VERSION "f33"

NS_ :

BS_:

BU_: C70 VC BMS CHG DASH PBX

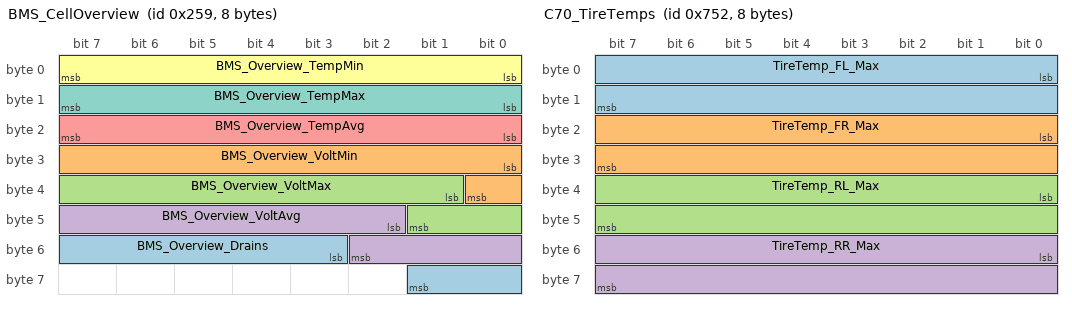
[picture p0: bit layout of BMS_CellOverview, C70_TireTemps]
BO_ 601 BMS_CellOverview: 8 BMS
 SG_ BMS_Overview_Drains : 51|7@1+ (1,0) [0|76] "" Vector__XXX
 SG_ BMS_Overview_VoltMin : 24|9@1+ (0.01,0) [0|5.12] "V"  DASH
 SG_ BMS_Overview_VoltMax : 33|9@1+ (0.01,0) [0|5.12] "V"  DASH
 SG_ BMS_Overview_VoltAvg : 42|9@1+ (0.01,0) [0|5.12] "V" Vector__XXX
 SG_ BMS_Overview_TempAvg : 16|8@1- (1,0) [-128|127] "C" Vector__XXX
 SG_ BMS_Overview_TempMin : 0|8@1- (1,0) [-128|127] "C" Vector__XXX
 SG_ BMS_Overview_TempMax : 8|8@1- (1,0) [-128|127] "C" Vector__XXX

BO_ 1791 C70_BrakePressures: 8 C70
 SG_ C70_BrakePressureFront : 0|16@1- (0.5,2500) [0|5000] "psi" Vector__XXX
 SG_ C70_BrakePressureRear : 16|16@1- (0.2,1250) [0|2500] "psi" Vector__XXX

BO_ 1874 C70_TireTemps: 8 C70
 SG_ TireTemp_FL_Max : 0|16@1+ (0.01,-100) [-20|950] "degC" Vector__XXX
 SG_ TireTemp_FR_Max : 16|16@1+ (0.01,-100) [-20|950] "degC" Vector__XXX
 SG_ TireTemp_RL_Max : 32|16@1+ (0.01,-100) [-20|950] "degC" Vector__XXX
 SG_ TireTemp_RR_Max : 48|16@1+ (0.01,-100) [-20|950] "degC" Vector__XXX

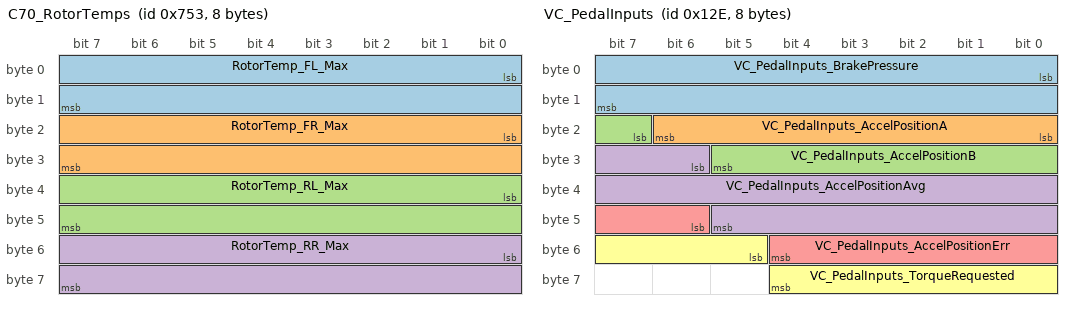
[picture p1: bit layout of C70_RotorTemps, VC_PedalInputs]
BO_ 1875 C70_RotorTemps: 8 C70
 SG_ RotorTemp_FL_Max : 0|16@1+ (0.01,-100) [-20|950] "degC" Vector__XXX
 SG_ RotorTemp_FR_Max : 16|16@1+ (0.01,-100) [-20|950] "degC" Vector__XXX
 SG_ RotorTemp_RL_Max : 32|16@1+ (0.01,-100) [-20|950] "degC" Vector__XXX
 SG_ RotorTemp_RR_Max : 48|16@1+ (0.01,-100) [-20|950] "degC" Vector__XXX

BO_ 301 VC_Status: 8 VC
 SG_ VC_Status_VehicleState : 0|4@1+ (1,0) [0|15] ""  DASH

BO_ 302 VC_PedalInputs: 8 VC
 SG_ VC_PedalInputs_BrakePressure : 0|16@1+ (0.1,0) [0|3000] "psi" Vector__XXX
 SG_ VC_PedalInputs_AccelPositionA : 16|7@1+ (1,0) [0|100] "%" Vector__XXX
 SG_ VC_PedalInputs_AccelPositionB : 23|7@1+ (1,0) [0|100] "%" Vector__XXX
 SG_ VC_PedalInputs_AccelPositionAvg : 30|16@1+ (0.1,0) [0|100] "%" Vector__XXX
 SG_ VC_PedalInputs_AccelPositionErr : 46|7@1+ (1,0) [0|100] "%" Vector__XXX
 SG_ VC_PedalInputs_TorqueRequested : 53|8@1+ (1,0) [0|254] "Nm" Vector__XXX

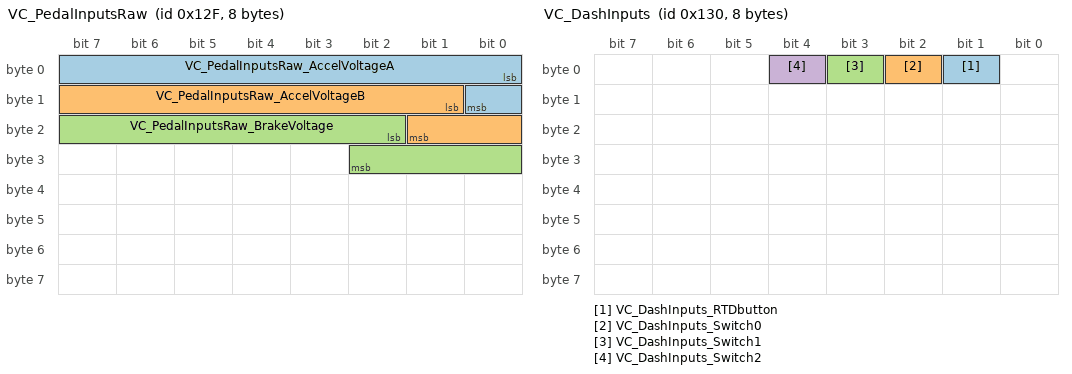
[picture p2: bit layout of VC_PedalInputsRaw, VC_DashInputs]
BO_ 303 VC_PedalInputsRaw: 8 VC
 SG_ VC_PedalInputsRaw_AccelVoltageA : 0|9@1+ (0.01,0) [0|5] "V" Vector__XXX
 SG_ VC_PedalInputsRaw_AccelVoltageB : 9|9@1+ (0.01,0) [0|5] "V" Vector__XXX
 SG_ VC_PedalInputsRaw_BrakeVoltage : 18|9@1+ (0.01,0) [0|5] "V" Vector__XXX

BO_ 304 VC_DashInputs: 8 VC
 SG_ VC_DashInputs_RTDbutton : 1|1@1+ (1,0) [0|1] "" Vector__XXX
 SG_ VC_DashInputs_Switch0 : 2|1@1+ (1,0) [0|1] "" Vector__XXX
 SG_ VC_DashInputs_Switch1 : 3|1@1+ (1,0) [0|1] "" Vector__XXX
 SG_ VC_DashInputs_Switch2 : 4|1@1+ (1,0) [0|1] "" Vector__XXX

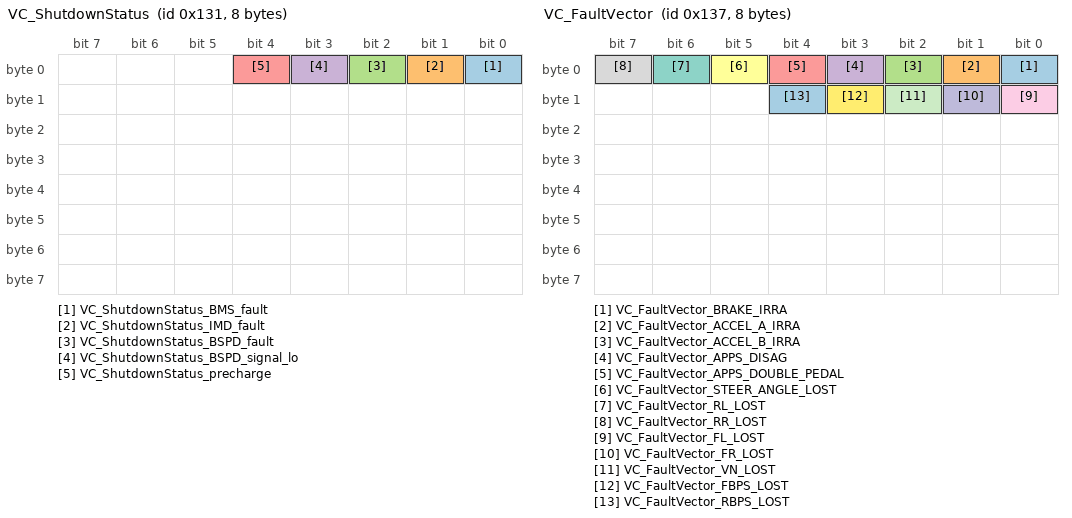
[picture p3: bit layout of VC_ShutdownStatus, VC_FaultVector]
BO_ 305 VC_ShutdownStatus: 8 VC
 SG_ VC_ShutdownStatus_BMS_fault : 0|1@1+ (1,0) [0|1] "" Vector__XXX
 SG_ VC_ShutdownStatus_IMD_fault : 1|1@1+ (1,0) [0|1] "" Vector__XXX
 SG_ VC_ShutdownStatus_BSPD_fault : 2|1@1+ (1,0) [0|1] "" Vector__XXX
 SG_ VC_ShutdownStatus_BSPD_signal_lo : 3|1@1+ (1,0) [0|1] "" Vector__XXX
 SG_ VC_ShutdownStatus_precharge : 4|1@1+ (1,0) [0|1] "" Vector__XXX

BO_ 311 VC_FaultVector: 8 VC
 SG_ VC_FaultVector_BRAKE_IRRA : 0|1@1+ (1,0) [0|1] ""  DASH
 SG_ VC_FaultVector_ACCEL_A_IRRA : 1|1@1+ (1,0) [0|1] ""  DASH
 SG_ VC_FaultVector_ACCEL_B_IRRA : 2|1@1+ (1,0) [0|1] ""  DASH
 SG_ VC_FaultVector_APPS_DISAG : 3|1@1+ (1,0) [0|1] ""  DASH
 SG_ VC_FaultVector_APPS_DOUBLE_PEDAL : 4|1@1+ (1,0) [0|1] ""  DASH
 SG_ VC_FaultVector_STEER_ANGLE_LOST : 5|1@1+ (1,0) [0|1] ""  DASH
 SG_ VC_FaultVector_RL_LOST : 6|1@1+ (1,0) [0|1] ""  DASH
 SG_ VC_FaultVector_RR_LOST : 7|1@1+ (1,0) [0|1] ""  DASH
 SG_ VC_FaultVector_FL_LOST : 8|1@1+ (1,0) [0|1] ""  DASH
 SG_ VC_FaultVector_FR_LOST : 9|1@1+ (1,0) [0|1] ""  DASH
 SG_ VC_FaultVector_VN_LOST : 10|1@1+ (1,0) [0|1] ""  DASH
 SG_ VC_FaultVector_FBPS_LOST : 11|1@1+ (1,0) [0|1] ""  DASH
 SG_ VC_FaultVector_RBPS_LOST : 12|1@1+ (1,0) [0|1] ""  DASH

BO_ 315 VC_HardFaultIndicator: 8 VC
 SG_ VC_HardFaultIndicator_task : 0|4@1+ (1,0) [0|15] ""  DASH

BO_ 316 VC_RTDSRequest: 8 VC
 SG_ VC_RequestRTDS : 0|1@1+ (1,0) [0|1] "" Vector__XXX

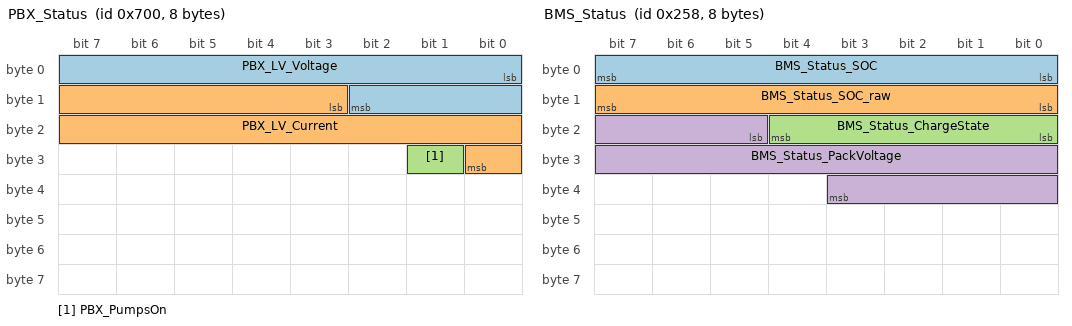
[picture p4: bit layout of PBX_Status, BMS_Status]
BO_ 1792 PBX_Status: 8 PBX
 SG_ PBX_LV_Voltage : 0|11@1+ (0.01,0) [0|20] "V" Vector__XXX
 SG_ PBX_LV_Current : 11|14@1+ (0.01,0) [0|100] "A" Vector__XXX
 SG_ PBX_PumpsOn : 25|1@1+ (1,0) [0|1] ""  VC

BO_ 514 BMS_Current_Limit: 8 BMS
 SG_ D1_Max_Discharge_Current : 0|16@1+ (1,0) [0|1000] "A" Vector__XXX
 SG_ D2_Max_Charge_Current : 16|16@1+ (1,0) [0|1000] "A" Vector__XXX

BO_ 600 BMS_Status: 8 BMS
 SG_ BMS_Status_SOC : 0|8@1+ (1,0) [0|100] "%"  DASH
 SG_ BMS_Status_SOC_raw : 8|8@1+ (1,0) [0|100] "%" Vector__XXX
 SG_ BMS_Status_ChargeState : 16|5@1+ (1,0) [0|5] "" Vector__XXX
 SG_ BMS_Status_PackVoltage : 21|15@1+ (0.1,0) [0|400] "V"  DASH

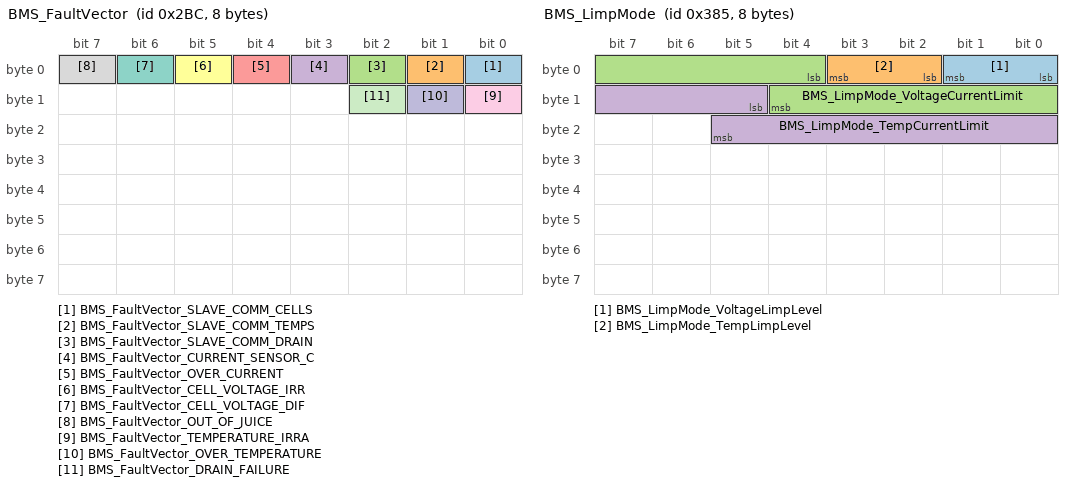
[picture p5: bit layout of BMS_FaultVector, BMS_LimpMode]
BO_ 700 BMS_FaultVector: 8 BMS
 SG_ BMS_FaultVector_SLAVE_COMM_CELLS : 0|1@1+ (1,0) [0|1] ""  DASH
 SG_ BMS_FaultVector_SLAVE_COMM_TEMPS : 1|1@1+ (1,0) [0|1] ""  DASH
 SG_ BMS_FaultVector_SLAVE_COMM_DRAIN : 2|1@1+ (1,0) [0|1] ""  DASH
 SG_ BMS_FaultVector_CURRENT_SENSOR_C : 3|1@1+ (1,0) [0|1] ""  DASH
 SG_ BMS_FaultVector_OVER_CURRENT : 4|1@1+ (1,0) [0|1] ""  DASH
 SG_ BMS_FaultVector_CELL_VOLTAGE_IRR : 5|1@1+ (1,0) [0|1] ""  DASH
 SG_ BMS_FaultVector_CELL_VOLTAGE_DIF : 6|1@1+ (1,0) [0|1] ""  DASH
 SG_ BMS_FaultVector_OUT_OF_JUICE : 7|1@1+ (1,0) [0|1] ""  DASH
 SG_ BMS_FaultVector_TEMPERATURE_IRRA : 8|1@1+ (1,0) [0|1] ""  DASH
 SG_ BMS_FaultVector_OVER_TEMPERATURE : 9|1@1+ (1,0) [0|1] ""  DASH
 SG_ BMS_FaultVector_DRAIN_FAILURE : 10|1@1+ (1,0) [0|1] ""  DASH

BO_ 701 BMS_FaultAlert: 8 BMS
 SG_ BMS_FaultAlert_code M : 0|6@1+ (1,0) [0|63] "" Vector__XXX
 SG_ BMS_FaultAlert_cell_comm_slave_b m0 : 6|8@1+ (1,0) [0|255] "" Vector__XXX
 SG_ BMS_FaultAlert_temp_comm_slave_b m1 : 6|8@1+ (1,0) [0|255] "" Vector__XXX
 SG_ BMS_FaultAlert_drain_comm_slave_ m2 : 6|8@1+ (1,0) [0|255] "" Vector__XXX
 SG_ BMS_FaultAlert_adc_error_code m3 : 6|8@1+ (1,0) [0|255] "" Vector__XXX
 SG_ BMS_FaultAlert_current m4 : 6|32@1+ (0.001,0) [0|2000] "A" Vector__XXX
 SG_ BMS_FaultAlert_irrational_voltag m5 : 6|9@1+ (0.01,0) [0|5.12] "V" Vector__XXX
 SG_ BMS_FaultAlert_voltage_diff m6 : 6|9@1+ (0.01,0) [0|5.12] "V" Vector__XXX
 SG_ BMS_FaultAlert_lowest_cell_volta m7 : 6|9@1+ (0.01,0) [0|5.12] "V" Vector__XXX
 SG_ BMS_FaultAlert_irrational_temper m8 : 6|16@1+ (0.01,0) [-327.68|327.67] "V" Vector__XXX
 SG_ BMS_FaultAlert_over_temperature m9 : 6|16@1+ (0.01,0) [-327.68|327.67] "V" Vector__XXX
 SG_ BMS_FaultAlert_failed_drain_cell m10 : 6|8@1+ (1,0) [0|255] "" Vector__XXX

BO_ 702 BMS_Voltages: 8 BMS
 SG_ BMS_Voltages_mux M : 0|8@1+ (1,0) [0|12] "" Vector__XXX
 SG_ BMS_Voltages_A1 m0 : 8|9@1+ (0.01,0) [0|5.12] "V" Vector__XXX
 SG_ BMS_Voltages_A2 m0 : 17|9@1+ (0.01,0) [0|5.12] "V" Vector__XXX
 SG_ BMS_Voltages_A3 m0 : 26|9@1+ (0.01,0) [0|5.12] "V" Vector__XXX
 SG_ BMS_Voltages_A4 m0 : 35|9@1+ (0.01,0) [0|5.12] "V" Vector__XXX
 SG_ BMS_Voltages_A5 m0 : 44|9@1+ (0.01,0) [0|5.12] "V" Vector__XXX
 SG_ BMS_Voltages_A6 m0 : 53|9@1+ (0.01,0) [0|5.12] "V" Vector__XXX
 SG_ BMS_Voltages_A7 m1 : 8|9@1+ (0.01,0) [0|5.12] "V" Vector__XXX
 SG_ BMS_Voltages_A8 m1 : 17|9@1+ (0.01,0) [0|5.12] "V" Vector__XXX
 SG_ BMS_Voltages_A9 m1 : 26|9@1+ (0.01,0) [0|5.12] "V" Vector__XXX
 SG_ BMS_Voltages_A10 m1 : 35|9@1+ (0.01,0) [0|5.12] "V" Vector__XXX
 SG_ BMS_Voltages_A11 m1 : 44|9@1+ (0.01,0) [0|5.12] "V" Vector__XXX
 SG_ BMS_Voltages_A12 m1 : 53|9@1+ (0.01,0) [0|5.12] "V" Vector__XXX
 SG_ BMS_Voltages_A13 m2 : 8|9@1+ (0.01,0) [0|5.12] "V" Vector__XXX
 SG_ BMS_Voltages_A14 m2 : 17|9@1+ (0.01,0) [0|5.12] "V" Vector__XXX
 SG_ BMS_Voltages_A15 m2 : 26|9@1+ (0.01,0) [0|5.12] "V" Vector__XXX
 SG_ BMS_Voltages_A16 m2 : 35|9@1+ (0.01,0) [0|5.12] "V" Vector__XXX
 SG_ BMS_Voltages_A17 m2 : 44|9@1+ (0.01,0) [0|5.12] "V" Vector__XXX
 SG_ BMS_Voltages_A18 m2 : 53|9@1+ (0.01,0) [0|5.12] "V" Vector__XXX
 SG_ BMS_Voltages_A19 m3 : 8|9@1+ (0.01,0) [0|5.12] "V" Vector__XXX
 SG_ BMS_Voltages_B1 m3 : 17|9@1+ (0.01,0) [0|5.12] "V" Vector__XXX
 SG_ BMS_Voltages_B2 m3 : 26|9@1+ (0.01,0) [0|5.12] "V" Vector__XXX
 SG_ BMS_Voltages_B3 m3 : 35|9@1+ (0.01,0) [0|5.12] "V" Vector__XXX
 SG_ BMS_Voltages_B4 m3 : 44|9@1+ (0.01,0) [0|5.12] "V" Vector__XXX
 SG_ BMS_Voltages_B5 m3 : 53|9@1+ (0.01,0) [0|5.12] "V" Vector__XXX
 SG_ BMS_Voltages_B6 m4 : 8|9@1+ (0.01,0) [0|5.12] "V" Vector__XXX
 SG_ BMS_Voltages_B7 m4 : 17|9@1+ (0.01,0) [0|5.12] "V" Vector__XXX
 SG_ BMS_Voltages_B8 m4 : 26|9@1+ (0.01,0) [0|5.12] "V" Vector__XXX
 SG_ BMS_Voltages_B9 m4 : 35|9@1+ (0.01,0) [0|5.12] "V" Vector__XXX
 SG_ BMS_Voltages_B10 m4 : 44|9@1+ (0.01,0) [0|5.12] "V" Vector__XXX
 SG_ BMS_Voltages_B11 m4 : 53|9@1+ (0.01,0) [0|5.12] "V" Vector__XXX
 SG_ BMS_Voltages_B12 m5 : 8|9@1+ (0.01,0) [0|5.12] "V" Vector__XXX
 SG_ BMS_Voltages_B13 m5 : 17|9@1+ (0.01,0) [0|5.12] "V" Vector__XXX
 SG_ BMS_Voltages_B14 m5 : 26|9@1+ (0.01,0) [0|5.12] "V" Vector__XXX
 SG_ BMS_Voltages_B15 m5 : 35|9@1+ (0.01,0) [0|5.12] "V" Vector__XXX
 SG_ BMS_Voltages_B16 m5 : 44|9@1+ (0.01,0) [0|5.12] "V" Vector__XXX
 SG_ BMS_Voltages_B17 m5 : 53|9@1+ (0.01,0) [0|5.12] "V" Vector__XXX
 SG_ BMS_Voltages_B18 m6 : 8|9@1+ (0.01,0) [0|5.12] "V" Vector__XXX
 SG_ BMS_Voltages_B19 m6 : 17|9@1+ (0.01,0) [0|5.12] "V" Vector__XXX
 SG_ BMS_Voltages_C1 m6 : 26|9@1+ (0.01,0) [0|5.12] "V" Vector__XXX
 SG_ BMS_Voltages_C2 m6 : 35|9@1+ (0.01,0) [0|5.12] "V" Vector__XXX
 SG_ BMS_Voltages_C3 m6 : 44|9@1+ (0.01,0) [0|5.12] "V" Vector__XXX
 SG_ BMS_Voltages_C4 m6 : 53|9@1+ (0.01,0) [0|5.12] "V" Vector__XXX
 SG_ BMS_Voltages_C5 m7 : 8|9@1+ (0.01,0) [0|5.12] "V" Vector__XXX
 SG_ BMS_Voltages_C6 m7 : 17|9@1+ (0.01,0) [0|5.12] "V" Vector__XXX
 SG_ BMS_Voltages_C7 m7 : 26|9@1+ (0.01,0) [0|5.12] "V" Vector__XXX
 SG_ BMS_Voltages_C8 m7 : 35|9@1+ (0.01,0) [0|5.12] "V" Vector__XXX
 SG_ BMS_Voltages_C9 m7 : 44|9@1+ (0.01,0) [0|5.12] "V" Vector__XXX
 SG_ BMS_Voltages_C10 m7 : 53|9@1+ (0.01,0) [0|5.12] "V" Vector__XXX
 SG_ BMS_Voltages_C11 m8 : 8|9@1+ (0.01,0) [0|5.12] "V" Vector__XXX
 SG_ BMS_Voltages_C12 m8 : 17|9@1+ (0.01,0) [0|5.12] "V" Vector__XXX
 SG_ BMS_Voltages_C13 m8 : 26|9@1+ (0.01,0) [0|5.12] "V" Vector__XXX
 SG_ BMS_Voltages_C14 m8 : 35|9@1+ (0.01,0) [0|5.12] "V" Vector__XXX
 SG_ BMS_Voltages_C15 m8 : 44|9@1+ (0.01,0) [0|5.12] "V" Vector__XXX
 SG_ BMS_Voltages_C16 m8 : 53|9@1+ (0.01,0) [0|5.12] "V" Vector__XXX
 SG_ BMS_Voltages_C17 m9 : 8|9@1+ (0.01,0) [0|5.12] "V" Vector__XXX
 SG_ BMS_Voltages_C18 m9 : 17|9@1+ (0.01,0) [0|5.12] "V" Vector__XXX
 SG_ BMS_Voltages_C19 m9 : 26|9@1+ (0.01,0) [0|5.12] "V" Vector__XXX
 SG_ BMS_Voltages_D1 m9 : 35|9@1+ (0.01,0) [0|5.12] "V" Vector__XXX
 SG_ BMS_Voltages_D2 m9 : 44|9@1+ (0.01,0) [0|5.12] "V" Vector__XXX
 SG_ BMS_Voltages_D3 m9 : 53|9@1+ (0.01,0) [0|5.12] "V" Vector__XXX
 SG_ BMS_Voltages_D4 m10 : 8|9@1+ (0.01,0) [0|5.12] "V" Vector__XXX
 SG_ BMS_Voltages_D5 m10 : 17|9@1+ (0.01,0) [0|5.12] "V" Vector__XXX
 SG_ BMS_Voltages_D6 m10 : 26|9@1+ (0.01,0) [0|5.12] "V" Vector__XXX
 SG_ BMS_Voltages_D7 m10 : 35|9@1+ (0.01,0) [0|5.12] "V" Vector__XXX
 SG_ BMS_Voltages_D8 m10 : 44|9@1+ (0.01,0) [0|5.12] "V" Vector__XXX
 SG_ BMS_Voltages_D9 m10 : 53|9@1+ (0.01,0) [0|5.12] "V" Vector__XXX
 SG_ BMS_Voltages_D10 m11 : 8|9@1+ (0.01,0) [0|5.12] "V" Vector__XXX
 SG_ BMS_Voltages_D11 m11 : 17|9@1+ (0.01,0) [0|5.12] "V" Vector__XXX
 SG_ BMS_Voltages_D12 m11 : 26|9@1+ (0.01,0) [0|5.12] "V" Vector__XXX
 SG_ BMS_Voltages_D13 m11 : 35|9@1+ (0.01,0) [0|5.12] "V" Vector__XXX
 SG_ BMS_Voltages_D14 m11 : 44|9@1+ (0.01,0) [0|5.12] "V" Vector__XXX
 SG_ BMS_Voltages_D15 m11 : 53|9@1+ (0.01,0) [0|5.12] "V" Vector__XXX
 SG_ BMS_Voltages_D16 m12 : 8|9@1+ (0.01,0) [0|5.12] "V" Vector__XXX
 SG_ BMS_Voltages_D17 m12 : 17|9@1+ (0.01,0) [0|5.12] "V" Vector__XXX
 SG_ BMS_Voltages_D18 m12 : 26|9@1+ (0.01,0) [0|5.12] "V" Vector__XXX
 SG_ BMS_Voltages_D19 m12 : 35|9@1+ (0.01,0) [0|5.12] "V" Vector__XXX

BO_ 703 BMS_ThermistorVoltages: 8 BMS
 SG_ BMS_ThermistorVoltages_mux M : 0|3@1+ (1,0) [0|5] "" Vector__XXX
 SG_ BMS_ThermistorVoltages_A1 m0 : 3|9@1+ (0.01,0) [0|5.12] "V" Vector__XXX
 SG_ BMS_ThermistorVoltages_A2 m0 : 12|9@1+ (0.01,0) [0|5.12] "V" Vector__XXX
 SG_ BMS_ThermistorVoltages_A3 m0 : 21|9@1+ (0.01,0) [0|5.12] "V" Vector__XXX
 SG_ BMS_ThermistorVoltages_A4 m0 : 30|9@1+ (0.01,0) [0|5.12] "V" Vector__XXX
 SG_ BMS_ThermistorVoltages_A5 m0 : 39|9@1+ (0.01,0) [0|5.12] "V" Vector__XXX
 SG_ BMS_ThermistorVoltages_A6 m0 : 48|9@1+ (0.01,0) [0|5.12] "V" Vector__XXX
 SG_ BMS_ThermistorVoltages_A7 m1 : 3|9@1+ (0.01,0) [0|5.12] "V" Vector__XXX
 SG_ BMS_ThermistorVoltages_A8 m1 : 12|9@1+ (0.01,0) [0|5.12] "V" Vector__XXX
 SG_ BMS_ThermistorVoltages_B1 m1 : 21|9@1+ (0.01,0) [0|5.12] "V" Vector__XXX
 SG_ BMS_ThermistorVoltages_B2 m1 : 30|9@1+ (0.01,0) [0|5.12] "V" Vector__XXX
 SG_ BMS_ThermistorVoltages_B3 m1 : 39|9@1+ (0.01,0) [0|5.12] "V" Vector__XXX
 SG_ BMS_ThermistorVoltages_B4 m1 : 48|9@1+ (0.01,0) [0|5.12] "V" Vector__XXX
 SG_ BMS_ThermistorVoltages_B5 m2 : 3|9@1+ (0.01,0) [0|5.12] "V" Vector__XXX
 SG_ BMS_ThermistorVoltages_B6 m2 : 12|9@1+ (0.01,0) [0|5.12] "V" Vector__XXX
 SG_ BMS_ThermistorVoltages_B7 m2 : 21|9@1+ (0.01,0) [0|5.12] "V" Vector__XXX
 SG_ BMS_ThermistorVoltages_B8 m2 : 30|9@1+ (0.01,0) [0|5.12] "V" Vector__XXX
 SG_ BMS_ThermistorVoltages_C1 m2 : 39|9@1+ (0.01,0) [0|5.12] "V" Vector__XXX
 SG_ BMS_ThermistorVoltages_C2 m2 : 48|9@1+ (0.01,0) [0|5.12] "V" Vector__XXX
 SG_ BMS_ThermistorVoltages_C3 m3 : 3|9@1+ (0.01,0) [0|5.12] "V" Vector__XXX
 SG_ BMS_ThermistorVoltages_C4 m3 : 12|9@1+ (0.01,0) [0|5.12] "V" Vector__XXX
 SG_ BMS_ThermistorVoltages_C5 m3 : 21|9@1+ (0.01,0) [0|5.12] "V" Vector__XXX
 SG_ BMS_ThermistorVoltages_C6 m3 : 30|9@1+ (0.01,0) [0|5.12] "V" Vector__XXX
 SG_ BMS_ThermistorVoltages_C7 m3 : 39|9@1+ (0.01,0) [0|5.12] "V" Vector__XXX
 SG_ BMS_ThermistorVoltages_C8 m3 : 48|9@1+ (0.01,0) [0|5.12] "V" Vector__XXX
 SG_ BMS_ThermistorVoltages_D1 m4 : 3|9@1+ (0.01,0) [0|5.12] "V" Vector__XXX
 SG_ BMS_ThermistorVoltages_D2 m4 : 12|9@1+ (0.01,0) [0|5.12] "V" Vector__XXX
 SG_ BMS_ThermistorVoltages_D3 m4 : 21|9@1+ (0.01,0) [0|5.12] "V" Vector__XXX
 SG_ BMS_ThermistorVoltages_D4 m4 : 30|9@1+ (0.01,0) [0|5.12] "V" Vector__XXX
 SG_ BMS_ThermistorVoltages_D5 m4 : 39|9@1+ (0.01,0) [0|5.12] "V" Vector__XXX
 SG_ BMS_ThermistorVoltages_D6 m4 : 48|9@1+ (0.01,0) [0|5.12] "V" Vector__XXX
 SG_ BMS_ThermistorVoltages_D7 m5 : 3|9@1+ (0.01,0) [0|5.12] "V" Vector__XXX
 SG_ BMS_ThermistorVoltages_D8 m5 : 12|9@1+ (0.01,0) [0|5.12] "V" Vector__XXX

BO_ 704 BMS_Temperatures: 8 BMS
 SG_ BMS_Temperatures_mux M : 0|3@1+ (1,0) [0|4] "" Vector__XXX
 SG_ BMS_Temperatures_A1 m0 : 3|8@1- (1,0) [-128|127] "C" Vector__XXX
 SG_ BMS_Temperatures_A2 m0 : 11|8@1- (1,0) [-128|127] "C" Vector__XXX
 SG_ BMS_Temperatures_A3 m0 : 19|8@1- (1,0) [-128|127] "C" Vector__XXX
 SG_ BMS_Temperatures_A4 m0 : 27|8@1- (1,0) [-128|127] "C" Vector__XXX
 SG_ BMS_Temperatures_A5 m0 : 35|8@1- (1,0) [-128|127] "C" Vector__XXX
 SG_ BMS_Temperatures_A6 m0 : 43|8@1- (1,0) [-128|127] "C" Vector__XXX
 SG_ BMS_Temperatures_A7 m0 : 51|8@1- (1,0) [-128|127] "C" Vector__XXX
 SG_ BMS_Temperatures_A8 m1 : 3|8@1- (1,0) [-128|127] "C" Vector__XXX
 SG_ BMS_Temperatures_B1 m1 : 11|8@1- (1,0) [-128|127] "C" Vector__XXX
 SG_ BMS_Temperatures_B2 m1 : 19|8@1- (1,0) [-128|127] "C" Vector__XXX
 SG_ BMS_Temperatures_B3 m1 : 27|8@1- (1,0) [-128|127] "C" Vector__XXX
 SG_ BMS_Temperatures_B4 m1 : 35|8@1- (1,0) [-128|127] "C" Vector__XXX
 SG_ BMS_Temperatures_B5 m1 : 43|8@1- (1,0) [-128|127] "C" Vector__XXX
 SG_ BMS_Temperatures_B6 m1 : 51|8@1- (1,0) [-128|127] "C" Vector__XXX
 SG_ BMS_Temperatures_B7 m2 : 3|8@1- (1,0) [-128|127] "C" Vector__XXX
 SG_ BMS_Temperatures_B8 m2 : 11|8@1- (1,0) [-128|127] "C" Vector__XXX
 SG_ BMS_Temperatures_C1 m2 : 19|8@1- (1,0) [-128|127] "C" Vector__XXX
 SG_ BMS_Temperatures_C2 m2 : 27|8@1- (1,0) [-128|127] "C" Vector__XXX
 SG_ BMS_Temperatures_C3 m2 : 35|8@1- (1,0) [-128|127] "C" Vector__XXX
 SG_ BMS_Temperatures_C4 m2 : 43|8@1- (1,0) [-128|127] "C" Vector__XXX
 SG_ BMS_Temperatures_C5 m2 : 51|8@1- (1,0) [-128|127] "C" Vector__XXX
 SG_ BMS_Temperatures_C6 m3 : 3|8@1- (1,0) [-128|127] "C" Vector__XXX
 SG_ BMS_Temperatures_C7 m3 : 11|8@1- (1,0) [-128|127] "C" Vector__XXX
 SG_ BMS_Temperatures_C8 m3 : 19|8@1- (1,0) [-128|127] "C" Vector__XXX
 SG_ BMS_Temperatures_D1 m3 : 27|8@1- (1,0) [-128|127] "C" Vector__XXX
 SG_ BMS_Temperatures_D2 m3 : 35|8@1- (1,0) [-128|127] "C" Vector__XXX
 SG_ BMS_Temperatures_D3 m3 : 43|8@1- (1,0) [-128|127] "C" Vector__XXX
 SG_ BMS_Temperatures_D4 m3 : 51|8@1- (1,0) [-128|127] "C" Vector__XXX
 SG_ BMS_Temperatures_D5 m4 : 3|8@1- (1,0) [-128|127] "C" Vector__XXX
 SG_ BMS_Temperatures_D6 m4 : 11|8@1- (1,0) [-128|127] "C" Vector__XXX
 SG_ BMS_Temperatures_D7 m4 : 19|8@1- (1,0) [-128|127] "C" Vector__XXX
 SG_ BMS_Temperatures_D8 m4 : 27|8@1- (1,0) [-128|127] "C" Vector__XXX

BO_ 800 BMS_DrainStatus: 8 BMS
 SG_ BMS_DrainStatus_mux M : 0|1@1+ (1,0) [0|1] "" Vector__XXX
 SG_ BMS_DrainStatus_A1 m0 : 1|1@1+ (1,0) [0|1] "" Vector__XXX
 SG_ BMS_DrainStatus_A2 m0 : 2|1@1+ (1,0) [0|1] "" Vector__XXX
 SG_ BMS_DrainStatus_A3 m0 : 3|1@1+ (1,0) [0|1] "" Vector__XXX
 SG_ BMS_DrainStatus_A4 m0 : 4|1@1+ (1,0) [0|1] "" Vector__XXX
 SG_ BMS_DrainStatus_A5 m0 : 5|1@1+ (1,0) [0|1] "" Vector__XXX
 SG_ BMS_DrainStatus_A6 m0 : 6|1@1+ (1,0) [0|1] "" Vector__XXX
 SG_ BMS_DrainStatus_A7 m0 : 7|1@1+ (1,0) [0|1] "" Vector__XXX
 SG_ BMS_DrainStatus_A8 m0 : 8|1@1+ (1,0) [0|1] "" Vector__XXX
 SG_ BMS_DrainStatus_A9 m0 : 9|1@1+ (1,0) [0|1] "" Vector__XXX
 SG_ BMS_DrainStatus_A10 m0 : 10|1@1+ (1,0) [0|1] "" Vector__XXX
 SG_ BMS_DrainStatus_A11 m0 : 11|1@1+ (1,0) [0|1] "" Vector__XXX
 SG_ BMS_DrainStatus_A12 m0 : 12|1@1+ (1,0) [0|1] "" Vector__XXX
 SG_ BMS_DrainStatus_A13 m0 : 13|1@1+ (1,0) [0|1] "" Vector__XXX
 SG_ BMS_DrainStatus_A14 m0 : 14|1@1+ (1,0) [0|1] "" Vector__XXX
 SG_ BMS_DrainStatus_A15 m0 : 15|1@1+ (1,0) [0|1] "" Vector__XXX
 SG_ BMS_DrainStatus_A16 m0 : 16|1@1+ (1,0) [0|1] "" Vector__XXX
 SG_ BMS_DrainStatus_A17 m0 : 17|1@1+ (1,0) [0|1] "" Vector__XXX
 SG_ BMS_DrainStatus_A18 m0 : 18|1@1+ (1,0) [0|1] "" Vector__XXX
 SG_ BMS_DrainStatus_A19 m0 : 19|1@1+ (1,0) [0|1] "" Vector__XXX
 SG_ BMS_DrainStatus_B1 m0 : 20|1@1+ (1,0) [0|1] "" Vector__XXX
 SG_ BMS_DrainStatus_B2 m0 : 21|1@1+ (1,0) [0|1] "" Vector__XXX
 SG_ BMS_DrainStatus_B3 m0 : 22|1@1+ (1,0) [0|1] "" Vector__XXX
 SG_ BMS_DrainStatus_B4 m0 : 23|1@1+ (1,0) [0|1] "" Vector__XXX
 SG_ BMS_DrainStatus_B5 m0 : 24|1@1+ (1,0) [0|1] "" Vector__XXX
 SG_ BMS_DrainStatus_B6 m0 : 25|1@1+ (1,0) [0|1] "" Vector__XXX
 SG_ BMS_DrainStatus_B7 m0 : 26|1@1+ (1,0) [0|1] "" Vector__XXX
 SG_ BMS_DrainStatus_B8 m0 : 27|1@1+ (1,0) [0|1] "" Vector__XXX
 SG_ BMS_DrainStatus_B9 m0 : 28|1@1+ (1,0) [0|1] "" Vector__XXX
 SG_ BMS_DrainStatus_B10 m0 : 29|1@1+ (1,0) [0|1] "" Vector__XXX
 SG_ BMS_DrainStatus_B11 m0 : 30|1@1+ (1,0) [0|1] "" Vector__XXX
 SG_ BMS_DrainStatus_B12 m0 : 31|1@1+ (1,0) [0|1] "" Vector__XXX
 SG_ BMS_DrainStatus_B13 m0 : 32|1@1+ (1,0) [0|1] "" Vector__XXX
 SG_ BMS_DrainStatus_B14 m0 : 33|1@1+ (1,0) [0|1] "" Vector__XXX
 SG_ BMS_DrainStatus_B15 m0 : 34|1@1+ (1,0) [0|1] "" Vector__XXX
 SG_ BMS_DrainStatus_B16 m0 : 35|1@1+ (1,0) [0|1] "" Vector__XXX
 SG_ BMS_DrainStatus_B17 m0 : 36|1@1+ (1,0) [0|1] "" Vector__XXX
 SG_ BMS_DrainStatus_B18 m0 : 37|1@1+ (1,0) [0|1] "" Vector__XXX
 SG_ BMS_DrainStatus_B19 m0 : 38|1@1+ (1,0) [0|1] "" Vector__XXX
 SG_ BMS_DrainStatus_C1 m0 : 39|1@1+ (1,0) [0|1] "" Vector__XXX
 SG_ BMS_DrainStatus_C2 m0 : 40|1@1+ (1,0) [0|1] "" Vector__XXX
 SG_ BMS_DrainStatus_C3 m0 : 41|1@1+ (1,0) [0|1] "" Vector__XXX
 SG_ BMS_DrainStatus_C4 m0 : 42|1@1+ (1,0) [0|1] "" Vector__XXX
 SG_ BMS_DrainStatus_C5 m0 : 43|1@1+ (1,0) [0|1] "" Vector__XXX
 SG_ BMS_DrainStatus_C6 m0 : 44|1@1+ (1,0) [0|1] "" Vector__XXX
 SG_ BMS_DrainStatus_C7 m0 : 45|1@1+ (1,0) [0|1] "" Vector__XXX
 SG_ BMS_DrainStatus_C8 m0 : 46|1@1+ (1,0) [0|1] "" Vector__XXX
 SG_ BMS_DrainStatus_C9 m0 : 47|1@1+ (1,0) [0|1] "" Vector__XXX
 SG_ BMS_DrainStatus_C10 m0 : 48|1@1+ (1,0) [0|1] "" Vector__XXX
 SG_ BMS_DrainStatus_C11 m0 : 49|1@1+ (1,0) [0|1] "" Vector__XXX
 SG_ BMS_DrainStatus_C12 m0 : 50|1@1+ (1,0) [0|1] "" Vector__XXX
 SG_ BMS_DrainStatus_C13 m0 : 51|1@1+ (1,0) [0|1] "" Vector__XXX
 SG_ BMS_DrainStatus_C14 m0 : 52|1@1+ (1,0) [0|1] "" Vector__XXX
 SG_ BMS_DrainStatus_C15 m0 : 53|1@1+ (1,0) [0|1] "" Vector__XXX
 SG_ BMS_DrainStatus_C16 m0 : 54|1@1+ (1,0) [0|1] "" Vector__XXX
 SG_ BMS_DrainStatus_C17 m0 : 55|1@1+ (1,0) [0|1] "" Vector__XXX
 SG_ BMS_DrainStatus_C18 m0 : 56|1@1+ (1,0) [0|1] "" Vector__XXX
 SG_ BMS_DrainStatus_C19 m0 : 57|1@1+ (1,0) [0|1] "" Vector__XXX
 SG_ BMS_DrainStatus_D1 m0 : 58|1@1+ (1,0) [0|1] "" Vector__XXX
 SG_ BMS_DrainStatus_D2 m0 : 59|1@1+ (1,0) [0|1] "" Vector__XXX
 SG_ BMS_DrainStatus_D3 m0 : 60|1@1+ (1,0) [0|1] "" Vector__XXX
 SG_ BMS_DrainStatus_D4 m0 : 61|1@1+ (1,0) [0|1] "" Vector__XXX
 SG_ BMS_DrainStatus_D5 m0 : 62|1@1+ (1,0) [0|1] "" Vector__XXX
 SG_ BMS_DrainStatus_D6 m0 : 63|1@1+ (1,0) [0|1] "" Vector__XXX
 SG_ BMS_DrainStatus_D7 m1 : 1|1@1+ (1,0) [0|1] "" Vector__XXX
 SG_ BMS_DrainStatus_D8 m1 : 2|1@1+ (1,0) [0|1] "" Vector__XXX
 SG_ BMS_DrainStatus_D9 m1 : 3|1@1+ (1,0) [0|1] "" Vector__XXX
 SG_ BMS_DrainStatus_D10 m1 : 4|1@1+ (1,0) [0|1] "" Vector__XXX
 SG_ BMS_DrainStatus_D11 m1 : 5|1@1+ (1,0) [0|1] "" Vector__XXX
 SG_ BMS_DrainStatus_D12 m1 : 6|1@1+ (1,0) [0|1] "" Vector__XXX
 SG_ BMS_DrainStatus_D13 m1 : 7|1@1+ (1,0) [0|1] "" Vector__XXX
 SG_ BMS_DrainStatus_D14 m1 : 8|1@1+ (1,0) [0|1] "" Vector__XXX
 SG_ BMS_DrainStatus_D15 m1 : 9|1@1+ (1,0) [0|1] "" Vector__XXX
 SG_ BMS_DrainStatus_D16 m1 : 10|1@1+ (1,0) [0|1] "" Vector__XXX
 SG_ BMS_DrainStatus_D17 m1 : 11|1@1+ (1,0) [0|1] "" Vector__XXX
 SG_ BMS_DrainStatus_D18 m1 : 12|1@1+ (1,0) [0|1] "" Vector__XXX
 SG_ BMS_DrainStatus_D19 m1 : 13|1@1+ (1,0) [0|1] "" Vector__XXX

BO_ 900 BMS_Current: 8 BMS
 SG_ BMS_InstCurrentFilt : 0|32@1- (0.001,0) [-100|250] "A"  DASH

BO_ 950 BMS_HardFaultIndicator: 8 BMS
 SG_ BMS_HardFaultIndicator_task : 0|4@1+ (1,0) [0|15] "" Vector__XXX

BO_ 951 BMS_Ref: 8 BMS
 SG_ BMS_Ref_mux M : 0|1@1+ (1,0) [0|1] "" Vector__XXX
 SG_ BMS_Ref_ref0 m0 : 1|9@1+ (0.01,0) [0|5.12] "V" Vector__XXX
 SG_ BMS_Ref_ref1 m0 : 10|9@1+ (0.01,0) [0|5.12] "V" Vector__XXX
 SG_ BMS_Ref_ref2 m0 : 19|9@1+ (0.01,0) [0|5.12] "V" Vector__XXX
 SG_ BMS_Ref_ref3 m0 : 28|9@1+ (0.01,0) [0|5.12] "V" Vector__XXX
 SG_ BMS_Ref_ref4 m0 : 37|9@1+ (0.01,0) [0|5.12] "V" Vector__XXX
 SG_ BMS_Ref_ref5 m0 : 46|9@1+ (0.01,0) [0|5.12] "V" Vector__XXX
 SG_ BMS_Ref_ref6 m1 : 1|9@1+ (0.01,0) [0|5.12] "V" Vector__XXX
 SG_ BMS_Ref_ref7 m1 : 10|9@1+ (0.01,0) [0|5.12] "V" Vector__XXX
 SG_ BMS_Ref_ref8 m1 : 19|9@1+ (0.01,0) [0|5.12] "V" Vector__XXX
 SG_ BMS_Ref_ref9 m1 : 28|9@1+ (0.01,0) [0|5.12] "V" Vector__XXX
 SG_ BMS_Ref_ref10 m1 : 37|9@1+ (0.01,0) [0|5.12] "V" Vector__XXX
 SG_ BMS_Ref_ref11 m1 : 46|9@1+ (0.01,0) [0|5.12] "V" Vector__XXX

BO_ 901 BMS_LimpMode: 8 BMS
 SG_ BMS_LimpMode_VoltageLimpLevel : 0|2@1+ (1,0) [0|4] "" Vector__XXX
 SG_ BMS_LimpMode_TempLimpLevel : 2|2@1+ (1,0) [0|4] "" Vector__XXX
 SG_ BMS_LimpMode_VoltageCurrentLimit : 4|9@1- (1,0) [-100|500] "A" Vector__XXX
 SG_ BMS_LimpMode_TempCurrentLimit : 13|9@1- (1,0) [-100|500] "A" Vector__XXX

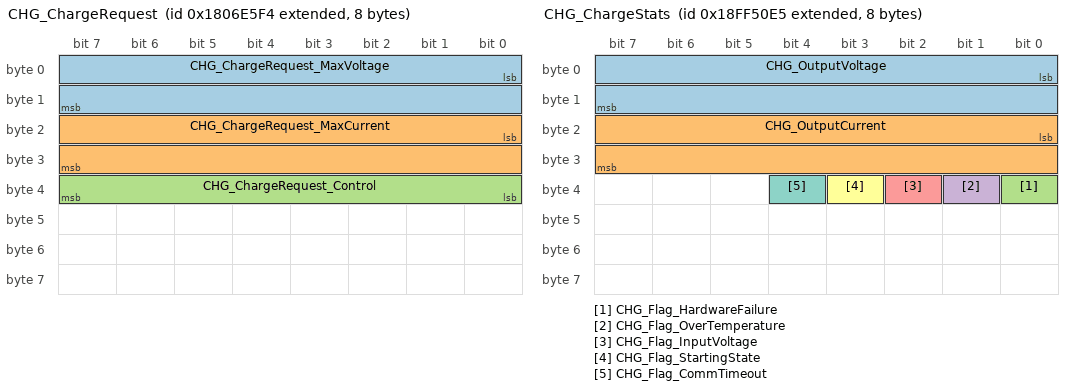
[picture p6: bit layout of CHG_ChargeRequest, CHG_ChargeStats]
BO_ 2550588916 CHG_ChargeRequest: 8 BMS
 SG_ CHG_ChargeRequest_MaxVoltage : 0|16@1+ (0.1,0) [0|6553.5] "V"  CHG
 SG_ CHG_ChargeRequest_MaxCurrent : 16|16@1+ (0.1,0) [0|6553.5] "A"  CHG
 SG_ CHG_ChargeRequest_Control : 32|8@1+ (1,0) [0|1] ""  CHG

BO_ 2566869221 CHG_ChargeStats: 8 CHG
 SG_ CHG_OutputVoltage : 0|16@1+ (0.1,0) [0|6553.5] "V" Vector__XXX
 SG_ CHG_OutputCurrent : 16|16@1+ (0.1,0) [0|6553.5] "A" Vector__XXX
 SG_ CHG_Flag_HardwareFailure : 32|1@1+ (1,0) [0|1] "" Vector__XXX
 SG_ CHG_Flag_OverTemperature : 33|1@1+ (1,0) [0|1] "" Vector__XXX
 SG_ CHG_Flag_InputVoltage : 34|1@1+ (1,0) [0|1] "" Vector__XXX
 SG_ CHG_Flag_StartingState : 35|1@1+ (1,0) [0|1] "" Vector__XXX
 SG_ CHG_Flag_CommTimeout : 36|1@1+ (1,0) [0|1] "" Vector__XXX

BO_ 504 SSDB_brake_pressure_front: 2 SSDB
 SG_ SSDB_brake_pressure_front : 0|12@1+ (1,0) [0|4095] "" Vector__XXX

BO_ 505 SSDB_steering_angle: 2 SSDB
 SG_ SSDB_steering_angle : 0|12@1+ (1,0) [0|4095] "" Vector__XXX

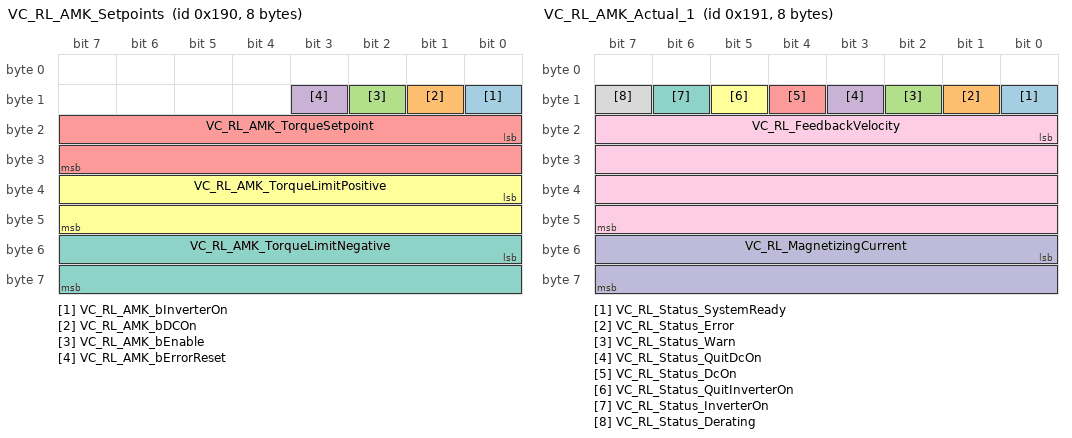
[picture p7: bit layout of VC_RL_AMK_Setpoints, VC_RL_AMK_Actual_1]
BO_ 400 VC_RL_AMK_Setpoints: 8 VC
 SG_ VC_RL_AMK_bInverterOn : 8|1@1+ (1,0) [0|1] "" Vector_XXX
 SG_ VC_RL_AMK_bDCOn : 9|1@1+ (1,0) [0|1] "" Vector_XXX
 SG_ VC_RL_AMK_bEnable : 10|1@1+ (1,0) [0|1] "" Vector_XXX
 SG_ VC_RL_AMK_bErrorReset : 11|1@1+ (1,0) [0|1] "" Vector_XXX
 SG_ VC_RL_AMK_TorqueSetpoint : 16|16@1- (0.1, 0) [-1000|1000] "% Mn" Vector_XXX
 SG_ VC_RL_AMK_TorqueLimitPositive : 32|16@1- (0.1, 0) [-3000|3000] "% Mn" Vector_XXX
 SG_ VC_RL_AMK_TorqueLimitNegative : 48|16@1- (0.1, 0) [-3000|3000] "% Mn" Vector_XXX

BO_ 401 VC_RL_AMK_Actual_1: 8 VC
 SG_ VC_RL_Status_SystemReady : 8|1@1+ (1,0) [0|1] "" Vector_XXX
 SG_ VC_RL_Status_Error : 9|1@1+ (1,0) [0|1] "" Vector_XXX
 SG_ VC_RL_Status_Warn : 10|1@1+ (1,0) [0|1] "" Vector_XXX
 SG_ VC_RL_Status_QuitDcOn : 11|1@1+ (1,0) [0|1] "" Vector_XXX
 SG_ VC_RL_Status_DcOn : 12|1@1+ (1,0) [0|1] "" Vector_XXX
 SG_ VC_RL_Status_QuitInverterOn : 13|1@1+ (1,0) [0|1] "" Vector_XXX
 SG_ VC_RL_Status_InverterOn : 14|1@1+ (1,0) [0|1] "" Vector_XXX
 SG_ VC_RL_Status_Derating : 15|1@1+ (1,0) [0|1] "" Vector_XXX
 SG_ VC_RL_FeedbackVelocity : 16|32@1- (0.0001,0) [-100000.0|100000.0] "rpm" Vector_XXX
 SG_ VC_RL_MagnetizingCurrent : 48|16@1- (1,0) [-32768|32767] "" Vector_XXX

BO_ 402 VC_RL_Info_1: 8 VC
 SG_ VC_RL_ErrorList1 : 0|32@1+ (1,0) [0|1] "" Vector_XXX
 SG_ VC_RL_ErrorList2 : 32|32@1+ (1,0) [0|1] "" Vector_XXX

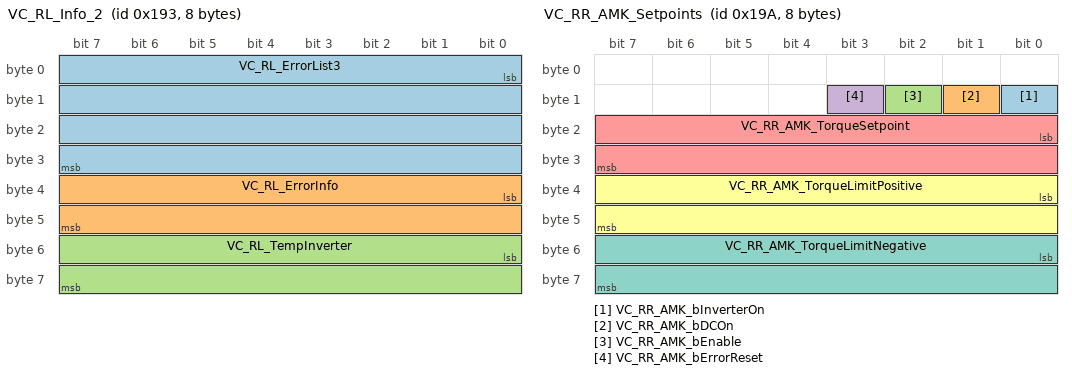
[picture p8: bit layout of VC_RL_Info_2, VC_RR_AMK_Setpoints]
BO_ 403 VC_RL_Info_2: 8 VC
 SG_ VC_RL_ErrorList3 : 0|32@1+ (1,0) [0|1] "" Vector_XXX
 SG_ VC_RL_ErrorInfo : 32|16@1+ (1,0) [-3276.8|3276.7] "" Vector_XXX
 SG_ VC_RL_TempInverter : 48|16@1- (0.1,0) [-32768|32767] "" Vector_XXX

BO_ 404 VC_RL_Info_3: 8 VC
 SG_ VC_RL_TempMotor : 0|16@1- (0.1,0) [-3276.8|3276.7] "degC" Vector_XXX
 SG_ VC_RL_TempInverter : 16|16@1- (0.1,0) [-32768|32767] "" Vector_XXX

BO_ 410 VC_RR_AMK_Setpoints: 8 VC
 SG_ VC_RR_AMK_bInverterOn : 8|1@1+ (1,0) [0|1] "" Vector_XXX
 SG_ VC_RR_AMK_bDCOn : 9|1@1+ (1,0) [0|1] "" Vector_XXX
 SG_ VC_RR_AMK_bEnable : 10|1@1+ (1,0) [0|1] "" Vector_XXX
 SG_ VC_RR_AMK_bErrorReset : 11|1@1+ (1,0) [0|1] "" Vector_XXX
 SG_ VC_RR_AMK_TorqueSetpoint : 16|16@1- (0.1, 0) [-1000|1000] "% Mn" Vector_XXX
 SG_ VC_RR_AMK_TorqueLimitPositive : 32|16@1- (0.1, 0) [-3000|3000] "% Mn" Vector_XXX
 SG_ VC_RR_AMK_TorqueLimitNegative : 48|16@1- (0.1, 0) [-3000|3000] "% Mn" Vector_XXX

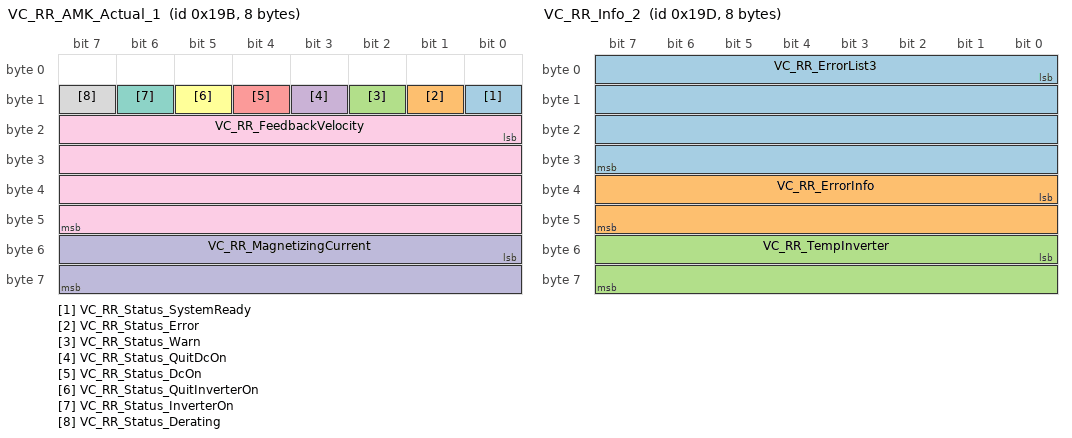
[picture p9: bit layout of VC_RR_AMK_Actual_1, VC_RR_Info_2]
BO_ 411 VC_RR_AMK_Actual_1: 8 VC
 SG_ VC_RR_Status_SystemReady : 8|1@1+ (1,0) [0|1] "" Vector_XXX
 SG_ VC_RR_Status_Error : 9|1@1+ (1,0) [0|1] "" Vector_XXX
 SG_ VC_RR_Status_Warn : 10|1@1+ (1,0) [0|1] "" Vector_XXX
 SG_ VC_RR_Status_QuitDcOn : 11|1@1+ (1,0) [0|1] "" Vector_XXX
 SG_ VC_RR_Status_DcOn : 12|1@1+ (1,0) [0|1] "" Vector_XXX
 SG_ VC_RR_Status_QuitInverterOn : 13|1@1+ (1,0) [0|1] "" Vector_XXX
 SG_ VC_RR_Status_InverterOn : 14|1@1+ (1,0) [0|1] "" Vector_XXX
 SG_ VC_RR_Status_Derating : 15|1@1+ (1,0) [0|1] "" Vector_XXX
 SG_ VC_RR_FeedbackVelocity : 16|32@1- (0.0001,0) [-100000.0|100000.0] "rpm" Vector_XXX
 SG_ VC_RR_MagnetizingCurrent : 48|16@1- (1,0) [-32768|32767] "" Vector_XXX

BO_ 412 VC_RR_Info_1: 8 VC
 SG_ VC_RR_ErrorList1 : 0|32@1+ (1,0) [0|1] "" Vector_XXX
 SG_ VC_RR_ErrorList2 : 32|32@1+ (1,0) [0|1] "" Vector_XXX

BO_ 413 VC_RR_Info_2: 8 VC
 SG_ VC_RR_ErrorList3 : 0|32@1+ (1,0) [0|1] "" Vector_XXX
 SG_ VC_RR_ErrorInfo : 32|16@1+ (1,0) [-3276.8|3276.7] "" Vector_XXX
 SG_ VC_RR_TempInverter : 48|16@1- (0.1,0) [-32768|32767] "" Vector_XXX

BO_ 414 VC_RR_Info_3: 8 VC
 SG_ VC_RR_TempMotor : 0|16@1- (0.1,0) [-3276.8|3276.7] "degC" Vector_XXX
 SG_ VC_RR_TempInverter : 16|16@1- (0.1,0) [-32768|32767] "" Vector_XXX

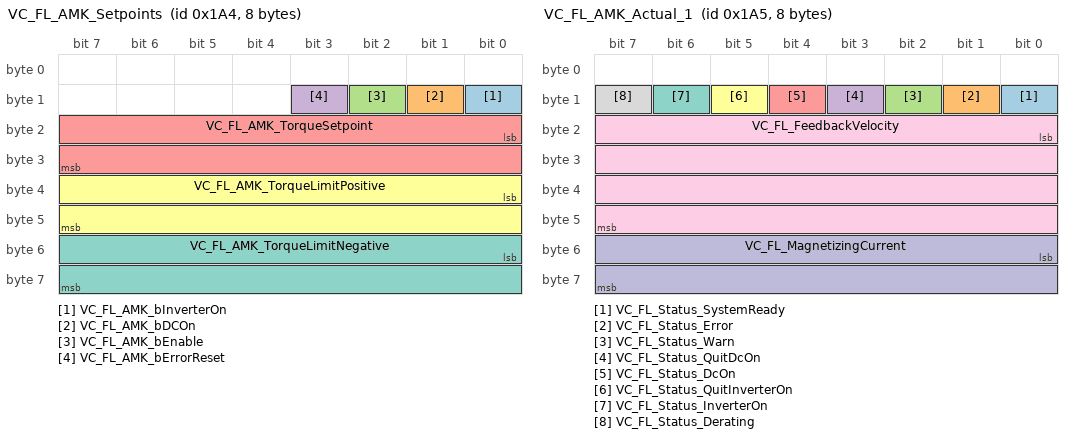
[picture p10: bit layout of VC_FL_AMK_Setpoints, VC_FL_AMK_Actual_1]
BO_ 420 VC_FL_AMK_Setpoints: 8 VC
 SG_ VC_FL_AMK_bInverterOn : 8|1@1+ (1,0) [0|1] "" Vector_XXX
 SG_ VC_FL_AMK_bDCOn : 9|1@1+ (1,0) [0|1] "" Vector_XXX
 SG_ VC_FL_AMK_bEnable : 10|1@1+ (1,0) [0|1] "" Vector_XXX
 SG_ VC_FL_AMK_bErrorReset : 11|1@1+ (1,0) [0|1] "" Vector_XXX
 SG_ VC_FL_AMK_TorqueSetpoint : 16|16@1- (0.1, 0) [-1000|1000] "% Mn" Vector_XXX
 SG_ VC_FL_AMK_TorqueLimitPositive : 32|16@1- (0.1, 0) [-3000|3000] "% Mn" Vector_XXX
 SG_ VC_FL_AMK_TorqueLimitNegative : 48|16@1- (0.1, 0) [-3000|3000] "% Mn" Vector_XXX

BO_ 421 VC_FL_AMK_Actual_1: 8 VC
 SG_ VC_FL_Status_SystemReady : 8|1@1+ (1,0) [0|1] "" Vector_XXX
 SG_ VC_FL_Status_Error : 9|1@1+ (1,0) [0|1] "" Vector_XXX
 SG_ VC_FL_Status_Warn : 10|1@1+ (1,0) [0|1] "" Vector_XXX
 SG_ VC_FL_Status_QuitDcOn : 11|1@1+ (1,0) [0|1] "" Vector_XXX
 SG_ VC_FL_Status_DcOn : 12|1@1+ (1,0) [0|1] "" Vector_XXX
 SG_ VC_FL_Status_QuitInverterOn : 13|1@1+ (1,0) [0|1] "" Vector_XXX
 SG_ VC_FL_Status_InverterOn : 14|1@1+ (1,0) [0|1] "" Vector_XXX
 SG_ VC_FL_Status_Derating : 15|1@1+ (1,0) [0|1] "" Vector_XXX
 SG_ VC_FL_FeedbackVelocity : 16|32@1- (0.0001,0) [-100000.0|100000.0] "rpm" Vector_XXX
 SG_ VC_FL_MagnetizingCurrent : 48|16@1- (1,0) [-32768|32767] "" Vector_XXX

BO_ 422 VC_Fl_Info_1: 8 VC
 SG_ VC_FL_ErrorList1 : 0|32@1+ (1,0) [0|1] "" Vector_XXX
 SG_ VC_FL_ErrorList2 : 32|32@1+ (1,0) [0|1] "" Vector_XXX

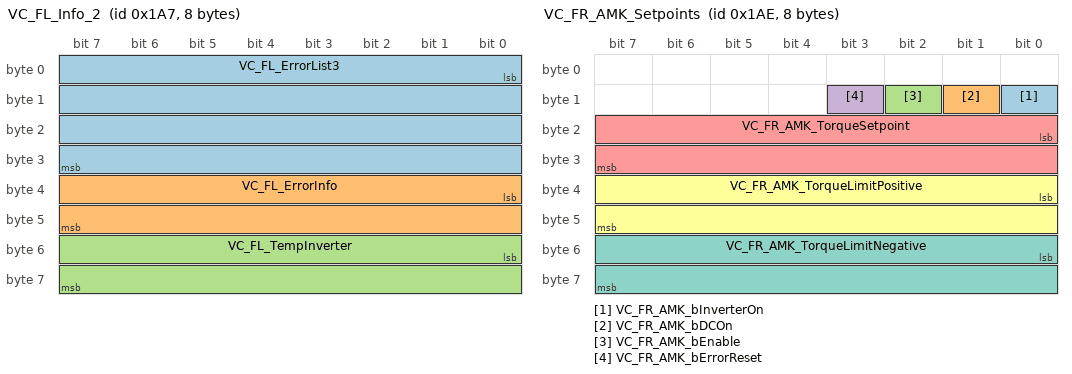
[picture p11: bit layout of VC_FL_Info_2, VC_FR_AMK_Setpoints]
BO_ 423 VC_FL_Info_2: 8 VC
 SG_ VC_FL_ErrorList3 : 0|32@1+ (1,0) [0|1] "" Vector_XXX
 SG_ VC_FL_ErrorInfo : 32|16@1+ (1,0) [-3276.8|3276.7] "" Vector_XXX
 SG_ VC_FL_TempInverter : 48|16@1- (0.1,0) [-32768|32767] "" Vector_XXX

BO_ 424 VC_FR_Info_3: 8 VC
 SG_ VC_FR_TempMotor : 0|16@1- (0.1,0) [-3276.8|3276.7] "degC" Vector_XXX
 SG_ VC_FR_TempInverter : 16|16@1- (0.1,0) [-32768|32767] "" Vector_XXX

BO_ 430 VC_FR_AMK_Setpoints: 8 VC
 SG_ VC_FR_AMK_bInverterOn : 8|1@1+ (1,0) [0|1] "" Vector_XXX
 SG_ VC_FR_AMK_bDCOn : 9|1@1+ (1,0) [0|1] "" Vector_XXX
 SG_ VC_FR_AMK_bEnable : 10|1@1+ (1,0) [0|1] "" Vector_XXX
 SG_ VC_FR_AMK_bErrorReset : 11|1@1+ (1,0) [0|1] "" Vector_XXX
 SG_ VC_FR_AMK_TorqueSetpoint : 16|16@1- (0.1, 0) [-1000|1000] "% Mn" Vector_XXX
 SG_ VC_FR_AMK_TorqueLimitPositive : 32|16@1- (0.1, 0) [-3000|3000] "% Mn" Vector_XXX
 SG_ VC_FR_AMK_TorqueLimitNegative : 48|16@1- (0.1, 0) [-3000|3000] "% Mn" Vector_XXX

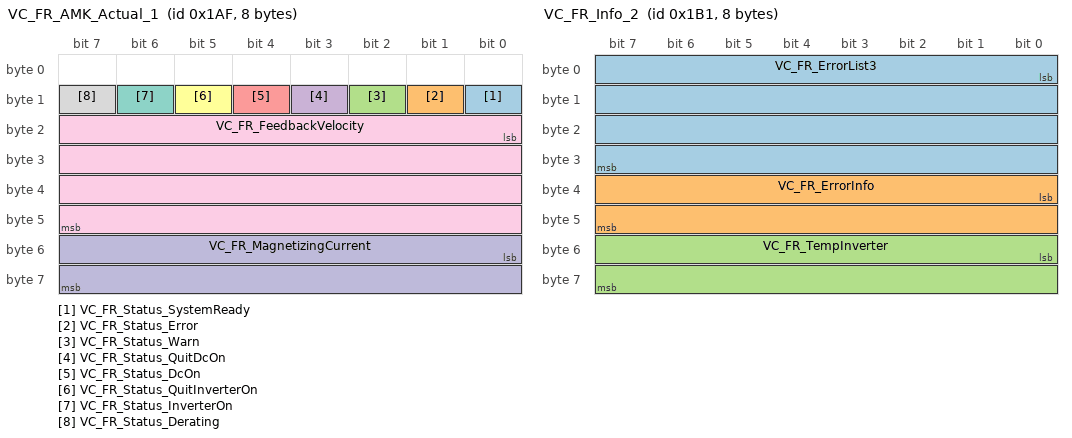
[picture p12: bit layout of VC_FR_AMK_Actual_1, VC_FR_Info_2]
BO_ 431 VC_FR_AMK_Actual_1: 8 VC
 SG_ VC_FR_Status_SystemReady : 8|1@1+ (1,0) [0|1] "" Vector_XXX
 SG_ VC_FR_Status_Error : 9|1@1+ (1,0) [0|1] "" Vector_XXX
 SG_ VC_FR_Status_Warn : 10|1@1+ (1,0) [0|1] "" Vector_XXX
 SG_ VC_FR_Status_QuitDcOn : 11|1@1+ (1,0) [0|1] "" Vector_XXX
 SG_ VC_FR_Status_DcOn : 12|1@1+ (1,0) [0|1] "" Vector_XXX
 SG_ VC_FR_Status_QuitInverterOn : 13|1@1+ (1,0) [0|1] "" Vector_XXX
 SG_ VC_FR_Status_InverterOn : 14|1@1+ (1,0) [0|1] "" Vector_XXX
 SG_ VC_FR_Status_Derating : 15|1@1+ (1,0) [0|1] "" Vector_XXX
 SG_ VC_FR_FeedbackVelocity : 16|32@1- (0.0001,0) [-100000.0|100000.0] "rpm" Vector_XXX
 SG_ VC_FR_MagnetizingCurrent : 48|16@1- (1,0) [-32768|32767] "" Vector_XXX

BO_ 432 VC_FR_Info_1: 8 VC
 SG_ VC_FR_ErrorList1 : 0|32@1+ (1,0) [0|1] "" Vector_XXX
 SG_ VC_FR_ErrorList2 : 32|32@1+ (1,0) [0|1] "" Vector_XXX

BO_ 433 VC_FR_Info_2: 8 VC
 SG_ VC_FR_ErrorList3 : 0|32@1+ (1,0) [0|1] "" Vector_XXX
 SG_ VC_FR_ErrorInfo : 32|16@1+ (1,0) [-3276.8|3276.7] "" Vector_XXX
 SG_ VC_FR_TempInverter : 48|16@1- (0.1,0) [-32768|32767] "" Vector_XXX

BO_ 434 VC_FR_Info_3: 8 VC
 SG_ VC_FR_TempMotor : 0|16@1- (0.1,0) [-3276.8|3276.7] "degC" Vector_XXX
 SG_ VC_FR_TempInverter : 16|16@1- (0.1,0) [-32768|32767] "" Vector_XXX

CM_ BU_ C70 "Bosch C70 Data Logger";
CM_ BU_ VC "Vehicle Controller";
CM_ BU_ BMS "Battery Management System";
CM_ BU_ CHG "Elcon HK-J Charger";
CM_ BU_ DASH "Dashboard Display";
CM_ BU_ SSDB "SSDB";
CM_ SG_ 601 BMS_Overview_Drains "Number of cells currently draining";
CM_ BO_ 1790 "Wheel speeds, relayed by C70";
CM_ BO_ 1791 "Brake Pressures, relayed by C70";
BA_DEF_ SG_  "SystemSignalLongSymbol" STRING ;
BA_DEF_DEF_  "SystemSignalLongSymbol" "";
BA_ "SystemSignalLongSymbol" SG_ 305 VC_ShutdownStatus_BSPD_signal_lo "VC_ShutdownStatus_BSPD_signal_lost";
BA_ "SystemSignalLongSymbol" SG_ 311 VC_FaultVector_BRAKE_SENSOR_IRRA "VC_FaultVector_BRAKE_SENSOR_IRRATIONAL";
BA_ "SystemSignalLongSymbol" SG_ 311 VC_FaultVector_ACCELERATOR_SENSO "VC_FaultVector_ACCELERATOR_SENSOR_IRRATIONAL";
BA_ "SystemSignalLongSymbol" SG_ 311 VC_FaultVector_APPS_SENSOR_DISAG "VC_FaultVector_APPS_SENSOR_DISAGREEMENT";
BA_ "SystemSignalLongSymbol" SG_ 469 D1_HV_Input_Current_Sensor_Valid "D1_HV_Input_Current_Sensor_Validity";
BA_ "SystemSignalLongSymbol" SG_ 700 BMS_FaultVector_SLAVE_COMM_DRAIN "BMS_FaultVector_SLAVE_COMM_DRAIN_REQUEST";
BA_ "SystemSignalLongSymbol" SG_ 700 BMS_FaultVector_CURRENT_SENSOR_C "BMS_FaultVector_CURRENT_SENSOR_COMM";
BA_ "SystemSignalLongSymbol" SG_ 700 BMS_FaultVector_CELL_VOLTAGE_IRR "BMS_FaultVector_CELL_VOLTAGE_IRRATIONAL";
BA_ "SystemSignalLongSymbol" SG_ 700 BMS_FaultVector_CELL_VOLTAGE_DIF "BMS_FaultVector_CELL_VOLTAGE_DIFF";
BA_ "SystemSignalLongSymbol" SG_ 700 BMS_FaultVector_TEMPERATURE_IRRA "BMS_FaultVector_TEMPERATURE_IRRATIONAL";
BA_ "SystemSignalLongSymbol" SG_ 701 BMS_FaultAlert_cell_comm_slave_b "BMS_FaultAlert_cell_comm_slave_board_num";
BA_ "SystemSignalLongSymbol" SG_ 701 BMS_FaultAlert_temp_comm_slave_b "BMS_FaultAlert_temp_comm_slave_board_num";
BA_ "SystemSignalLongSymbol" SG_ 701 BMS_FaultAlert_drain_comm_slave_ "BMS_FaultAlert_drain_comm_slave_board_num";
BA_ "SystemSignalLongSymbol" SG_ 701 BMS_FaultAlert_irrational_voltag "BMS_FaultAlert_irrational_voltage";
BA_ "SystemSignalLongSymbol" SG_ 701 BMS_FaultAlert_lowest_cell_volta "BMS_FaultAlert_lowest_cell_voltage";
BA_ "SystemSignalLongSymbol" SG_ 701 BMS_FaultAlert_irrational_temper "BMS_FaultAlert_irrational_temperature";
VAL_ 301 VC_Status_VehicleState 0 "VehicleState_NOT_READY" 1 "VehicleState_STARTUP" 2 "VehicleState_READY_TO_DRIVE" 3 "VehicleState_FAULTED" ;
VAL_ 315 VC_HardFaultIndicator_task 0 "unknown" 1 "task_100Hz" ;
VAL_ 192 Direction_Command 0 "CW" 1 "CCW" ;
VAL_ 192 Inverter_Discharge 0 "Discharge Disable" 1 "Discharge Enable (if EEPROM parameter is set)" ;
VAL_ 170 D2_Inverter_State 0 "Power up" 1 "Stop" 2 "Open Loop" 3 "Closed Loop" 4 "Internal State" 5 "Internal State" 6 "Internal State" 7 "Internal State" 8 "Idle Run" 9 "Idle Stop" 10 "Internal State" 11 "Intern State" 12 "Internal State" ;
VAL_ 170 D1_VSM_State 0 "VSM Start State" 1 "Pre-Charge Init state" 2 "pre-charge active state" 3 "pre-charge complete state" 4 "VSM wait state" 5 "VSM ready state" 6 "Motor Running State" 7 "blink fault code state" 14 "Shutdown state for Key Switch Mode 1" 15 "Reset the inverter" ;
VAL_ 600 BMS_Status_ChargeState 0 "ChargeState_DISCONNECTED" 1 "ChargeState_CONNECTED_CHARGING" 2 "ChargeState_CONNECTED_BALANCING" 3 "ChargeState_CONNECTED_BALANCE_SENSING" 4 "ChargeState_CONNECTED_COMPLETE" 5 "ChargeState_CONNECTED_FAULTED";
VAL_ 701 BMS_FaultAlert_code 0 "FaultCode_SLAVE_COMM_CELLS" 1 "FaultCode_SLAVE_COMM_TEMPS" 2 "FaultCode_SLAVE_COMM_DRAIN_REQUEST" 3 "FaultCode_CURRENT_SENSOR_COMM" 4 "FaultCode_OVER_CURRENT" 5 "FaultCode_CELL_VOLTAGE_IRRATIONAL" 6 "FaultCode_CELL_VOLTAGE_DIFF" 7 "Faultcode_OUT_OF_JUICE" 8 "FaultCode_TEMPERATURE_IRRATIONAL" 9 "FaultCode_OVER_TEMP" 10 "FaultCode_DRAIN_FAILURE" ;
VAL_ 950 BMS_HardFaultIndicator_task 0 "unknown" 1 "task_1Hz" 2 "task_10Hz" 3 "task_1kHz" 4 "can_rx_task" ;
VAL_ 901 BMS_LimpMode_VoltageLimpLevel 0 "LimpModeLevel_NO_LIMP" 1 "LimpModeLevel_LEVEL_1" 2 "LimpModeLevel_LEVEL_2" 3 "LimpModeLevel_LEVEL_3" ;
VAL_ 901 BMS_LimpMode_TempLimpLevel 0 "LimpModeLevel_NO_LIMP" 1 "LimpModeLevel_LEVEL_1" 2 "LimpModeLevel_LEVEL_2" 3 "LimpModeLevel_LEVEL_3" ;
